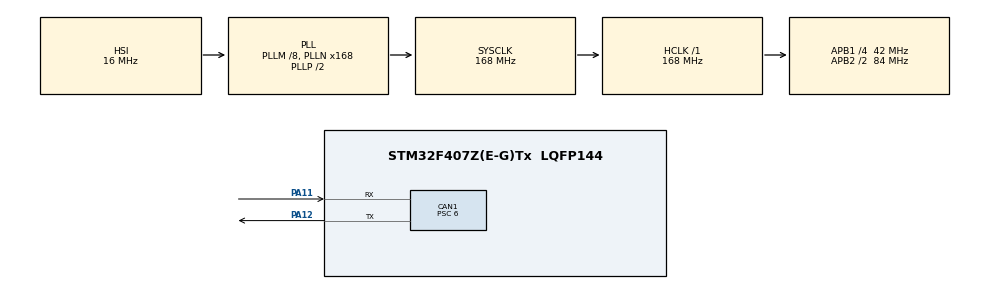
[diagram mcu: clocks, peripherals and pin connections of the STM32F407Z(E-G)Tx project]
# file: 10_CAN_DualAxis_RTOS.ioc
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CAN1.ABOM=ENABLE
CAN1.BS1=CAN_BS1_10TQ
CAN1.BS2=CAN_BS2_3TQ
CAN1.CalculateBaudRate=500000
CAN1.CalculateTimeBit=2000
CAN1.CalculateTimeQuantum=142.85714285714286
CAN1.NART=DISABLE
CAN1.Prescaler=6
FREERTOS.Queues01=MotionCommandQueue,5,16,1,Dynamic,NULL,NULL;MotionResultQueue,5,8,1,Dynamic,NULL,NULL
FREERTOS.Tasks01=MotionTask,24,128,StartMotionTask,Default,NULL,Dynamic,NULL,NULL;SystemTask,24,128,StartSystemTask,Default,NULL,Dynamic,NULL,NULL
Mcu.Family=STM32F4
Mcu.Name=STM32F407Z(E-G)Tx
Mcu.Package=LQFP144
NVIC.CAN1_RX0_IRQn=true\:5\:0\:false\:false\:true\:true\:true\:true\:true
NVIC.PriorityGroup=NVIC_PRIORITYGROUP_4
NVIC.TIM6_DAC_IRQn=true\:15\:0\:false\:false\:true\:false\:false\:true\:true
NVIC.TimeBase=TIM6_DAC_IRQn
NVIC.TimeBaseIP=TIM6
PA11.Mode=CAN_Activate
PA11.Signal=CAN1_RX
PA12.Mode=CAN_Activate
PA12.Signal=CAN1_TX
PA13.Mode=Serial_Wire
PA13.Signal=SYS_JTMS-SWDIO
PA14.Mode=Serial_Wire
PA14.Signal=SYS_JTCK-SWCLK
PH0-OSC_IN.Mode=HSE-External-Oscillator
PH0-OSC_IN.Signal=RCC_OSC_IN
PH1-OSC_OUT.Mode=HSE-External-Oscillator
PH1-OSC_OUT.Signal=RCC_OSC_OUT
ProjectManager.HeapSize=0x200
ProjectManager.StackSize=0x400
ProjectManager.TargetToolchain=MDK-ARM V5.32
RCC.48MHZClocksFreq_Value=84000000
RCC.AHBFreq_Value=168000000
RCC.APB1CLKDivider=RCC_HCLK_DIV4
RCC.APB1Freq_Value=42000000
RCC.APB1TimFreq_Value=84000000
RCC.APB2CLKDivider=RCC_HCLK_DIV2
RCC.APB2Freq_Value=84000000
RCC.APB2TimFreq_Value=168000000
RCC.CortexFreq_Value=168000000
RCC.HCLKFreq_Value=168000000
RCC.HSE_VALUE=25000000
RCC.HSI_VALUE=16000000
RCC.LSE_VALUE=32768
RCC.PLLM=8
RCC.PLLN=168
RCC.SYSCLKFreq_VALUE=168000000
RCC.SYSCLKSource=RCC_SYSCLKSOURCE_PLLCLK
RCC.VCOOutputFreq_Value=336000000
VP_FREERTOS_VS_CMSIS_V2.Mode=CMSIS_V2
VP_SYS_VS_tim6.Mode=TIM6
board=custom

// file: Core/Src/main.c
/* USER CODE BEGIN Header */
/**
  ******************************************************************************
  * @file           : main.c
  * @brief          : Main program body
  ******************************************************************************
  * @attention
  *
  * Copyright (c) 2026 STMicroelectronics.
  * All rights reserved.
  *
  * This software is licensed under terms that can be found in the LICENSE file
  * in the root directory of this software component.
  * If no LICENSE file comes with this software, it is provided AS-IS.
  *
  ******************************************************************************
  */
/* USER CODE END Header */
#include "main.h"
#include "cmsis_os.h"
#include "can.h"
#include "gpio.h"

/* USER CODE BEGIN Includes */
#include "mks_motor.h"
#include "motion_control.h"
#include "system_control.h"
/* USER CODE END Includes */

/* USER CODE BEGIN PV */
 MotionController_t Motion_X;
 MotionController_t Motion_Y;
/* USER CODE END PV */

void SystemClock_Config(void);
void MX_FREERTOS_Init(void);

int main(void)
{

  /* MCU Configuration--------------------------------------------------------*/

  /* Reset of all peripherals, Initializes the Flash interface and the Systick. */
  HAL_Init();

  /* Configure the system clock */
  SystemClock_Config();

  /* Initialize all configured peripherals */
  MX_GPIO_Init();
  MX_CAN1_Init();
  /* USER CODE BEGIN 2 */

MKS_Motor_System_Init();      // 初始化你自己的电机结构体，比如 ID
STM32_bxCAN_Filter_Config();     // 配置 CAN 接收过滤器
Motion_Init(&Motion_X, &Motor_X);
Motion_Init(&Motion_Y, &Motor_Y);

System_Init(&Motion_X, &Motion_Y);

if (HAL_CAN_Start(&hcan1) != HAL_OK)
{
    Error_Handler();
}

if (HAL_CAN_ActivateNotification(
        &hcan1,
        CAN_IT_RX_FIFO0_MSG_PENDING) != HAL_OK)// 启动 CAN 外设，打开 FIFO0 接收中断通知
{
    Error_Handler();
}

  /* USER CODE END 2 */

  /* Init scheduler */
  osKernelInitialize();  /* Call init function for freertos objects (in cmsis_os2.c) */
  MX_FREERTOS_Init();

  /* Start scheduler */
  osKernelStart();

  /* We should never get here as control is now taken by the scheduler */

  /* Infinite loop */
  while (1)
  {

  }
}

void SystemClock_Config(void)
{
  RCC_OscInitTypeDef RCC_OscInitStruct = {0};
  RCC_ClkInitTypeDef RCC_ClkInitStruct = {0};

  /** Configure the main internal regulator output voltage
  */
  __HAL_RCC_PWR_CLK_ENABLE();
  __HAL_PWR_VOLTAGESCALING_CONFIG(PWR_REGULATOR_VOLTAGE_SCALE1);

  /** Initializes the RCC Oscillators according to the specified parameters
  * in the RCC_OscInitTypeDef structure.
  */
  RCC_OscInitStruct.OscillatorType = RCC_OSCILLATORTYPE_HSI;
  RCC_OscInitStruct.HSIState = RCC_HSI_ON;
  RCC_OscInitStruct.HSICalibrationValue = RCC_HSICALIBRATION_DEFAULT;
  RCC_OscInitStruct.PLL.PLLState = RCC_PLL_ON;
  RCC_OscInitStruct.PLL.PLLSource = RCC_PLLSOURCE_HSI;
  RCC_OscInitStruct.PLL.PLLM = 8;
  RCC_OscInitStruct.PLL.PLLN = 168;
  RCC_OscInitStruct.PLL.PLLP = RCC_PLLP_DIV2;
  RCC_OscInitStruct.PLL.PLLQ = 4;
  if (HAL_RCC_OscConfig(&RCC_OscInitStruct) != HAL_OK)
  {
    Error_Handler();
  }

  /** Initializes the CPU, AHB and APB buses clocks
  */
  RCC_ClkInitStruct.ClockType = RCC_CLOCKTYPE_HCLK|RCC_CLOCKTYPE_SYSCLK
                              |RCC_CLOCKTYPE_PCLK1|RCC_CLOCKTYPE_PCLK2;
  RCC_ClkInitStruct.SYSCLKSource = RCC_SYSCLKSOURCE_PLLCLK;
  RCC_ClkInitStruct.AHBCLKDivider = RCC_SYSCLK_DIV1;
  RCC_ClkInitStruct.APB1CLKDivider = RCC_HCLK_DIV4;
  RCC_ClkInitStruct.APB2CLKDivider = RCC_HCLK_DIV2;

  if (HAL_RCC_ClockConfig(&RCC_ClkInitStruct, FLASH_LATENCY_5) != HAL_OK)
  {
    Error_Handler();
  }
}

void HAL_TIM_PeriodElapsedCallback(TIM_HandleTypeDef *htim)
{
  if (htim->Instance == TIM6)
  {
    HAL_IncTick();
  }
}

void Error_Handler(void)
{
  __disable_irq();
  while (1)
  {
  }
}

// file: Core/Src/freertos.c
/* USER CODE BEGIN Header */
/**
  ******************************************************************************
  * File Name          : freertos.c
  * Description        : Code for freertos applications
  ******************************************************************************
  * @attention
  *
  * Copyright (c) 2026 STMicroelectronics.
  * All rights reserved.
  *
  * This software is licensed under terms that can be found in the LICENSE file
  * in the root directory of this software component.
  * If no LICENSE file comes with this software, it is provided AS-IS.
  *
  ******************************************************************************
  */
/* USER CODE END Header */

#include "FreeRTOS.h"
#include "task.h"
#include "main.h"
#include "cmsis_os.h"

/* USER CODE BEGIN Includes */
#include "motion_control.h"
#include "system_control.h"
/* USER CODE END Includes */

/* USER CODE BEGIN Variables */
extern MotionController_t Motion_X;
extern MotionController_t Motion_Y;

/* USER CODE END Variables */
/* Definitions for MotionTask */
osThreadId_t MotionTaskHandle;
const osThreadAttr_t MotionTask_attributes = {
  .name = "MotionTask",
  .stack_size = 128 * 4,
  .priority = (osPriority_t) osPriorityNormal,
};
/* Definitions for SystemTask */
osThreadId_t SystemTaskHandle;
const osThreadAttr_t SystemTask_attributes = {
  .name = "SystemTask",
  .stack_size = 128 * 4,
  .priority = (osPriority_t) osPriorityNormal,
};
/* Definitions for MotionCommandQueue */
osMessageQueueId_t MotionCommandQueueHandle;
const osMessageQueueAttr_t MotionCommandQueue_attributes = {
  .name = "MotionCommandQueue"
};
/* Definitions for MotionResultQueue */
osMessageQueueId_t MotionResultQueueHandle;
const osMessageQueueAttr_t MotionResultQueue_attributes = {
  .name = "MotionResultQueue"
};

void StartMotionTask(void *argument);
void StartSystemTask(void *argument);

void MX_FREERTOS_Init(void); /* (MISRA C 2004 rule 8.1) */

void MX_FREERTOS_Init(void) {

  /* Create the queue(s) */
  /* creation of MotionCommandQueue */
  MotionCommandQueueHandle = osMessageQueueNew (5, 16, &MotionCommandQueue_attributes);

  /* creation of MotionResultQueue */
  MotionResultQueueHandle = osMessageQueueNew (5, 8, &MotionResultQueue_attributes);

  /* Create the thread(s) */
  /* creation of MotionTask */
  MotionTaskHandle = osThreadNew(StartMotionTask, NULL, &MotionTask_attributes);

  /* creation of SystemTask */
  SystemTaskHandle = osThreadNew(StartSystemTask, NULL, &SystemTask_attributes);

}

void StartMotionTask(void *argument)
{
  /* USER CODE BEGIN StartMotionTask */
  /* Infinite loop */
 MotionCommand_t received_command;
    MotionResult_t result_message;

    MotionController_t *target_motion = NULL;
    MotionController_t *active_motion = NULL;
     uint32_t active_command_id = 0U;
    osStatus_t status;

    for (;;)
    {
        /* ��ǰû���˶���������ִ�У��ŴӶ���ȡ��һ�� */
        if (active_motion == NULL)
        {
            status = osMessageQueueGet(MotionCommandQueueHandle,
                                       &received_command,
                                       NULL,
                                       0U);

            if (status == osOK)
            {
                if (received_command.axis == MOTION_AXIS_X)
                {
                    target_motion = &Motion_X;
                }
                else if (received_command.axis == MOTION_AXIS_Y)
                {
                    target_motion = &Motion_Y;
                }
                else
                {
                    target_motion = NULL;
                }

                if (target_motion != NULL)
                {
                    if (received_command.type == MOTION_CMD_ENABLE)
                    {
                        MKS_Set_Enable_State(target_motion->motor,
                                             received_command.enable);
                    }
                    else if (received_command.type == MOTION_CMD_MOVE_REL)
                    {
                        Motion_StartRelative(
                            target_motion,
                            received_command.displacement,
                            received_command.speed,
                            received_command.acceleration);

                       /* 记住当前正在执行的是哪一号命令 */
                        active_command_id = received_command.command_id;
                        active_motion = target_motion;
                    }
                }
            }
        }

        /* �����Ƿ���������������ƽ�����״̬�� */
        Motion_Task(&Motion_X);
        Motion_Task(&Motion_Y);

        /* ��ǰ�˶���ɣ�������һ�ִӶ���ȡ������ */
       if ((active_motion != NULL) &&
    (active_motion->motion_done == 1U))
{
    result_message.command_id = active_command_id;
    result_message.result = 0U;  /* 0 暂时表示执行成功 */

    if (osMessageQueuePut(MotionResultQueueHandle,
                          &result_message,
                          0U,
                          osWaitForever) == osOK)
    {
        active_command_id = 0U;
        active_motion = NULL;
    }
}
        osDelay(10U);
    }
  /* USER CODE END StartMotionTask */
}

void StartSystemTask(void *argument)
{
  /* USER CODE BEGIN StartSystemTask */
  /* Infinite loop */
 for (;;)
    {
        System_Task();

        osDelay(10U);
    }

  /* USER CODE END StartSystemTask */
}
